# K1921VG1T register map
Vendor: NIIET; Series: K1921VGx; File version: 2.8
CPU: other r0p1, little endian, MPU, FPU, 4 interrupt priority bits
Registers are 32-bit, read-write, reset 0x0 unless marked. A register's access mark holds for its fields unless they carry their own. Offsets are from the block's base; [hi:lo] are bit positions; lines under a group give offsets from that group; {n}, {i} and the like mark numbered series; 'fields as' and 'values as' point back to an identical list.

## USBDC0 — USBDC control registers
Base 0x41080000
Same registers: USBDC1 0x41090000
{0x0+0x10*i} EPO[{i}] (i=0..3) group
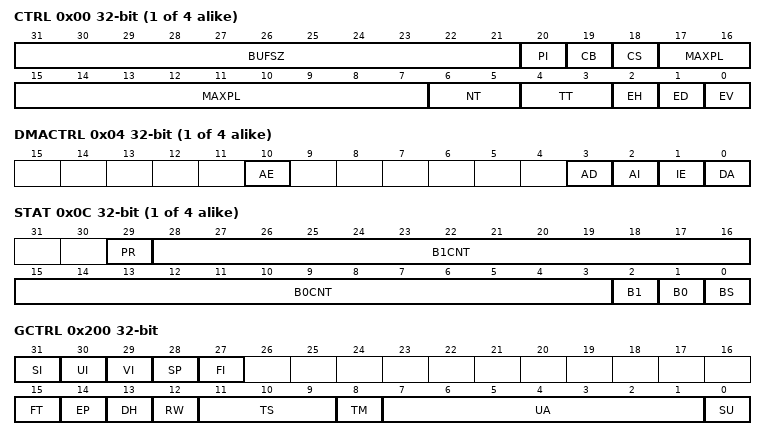
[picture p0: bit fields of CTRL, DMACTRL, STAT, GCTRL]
  0x00 CTRL — OUT Endpoint control register
    [31:21] BUFSZ ro — Buffer size
    [20] PI — Packet received interrupt
    [19] CB — Clear buffers
    [18] CS — Control stall
    [17:7] MAXPL — Maximum payload
    [6:5] NT — Number of transactions
    [4:3] TT — Transfer type
      0=CTRL (Control type of EPO); 1=ISOCH (Isochronous type of EPO); 2=BULK (Bulk type of EPO); 3=INTERRUPT (Interrupt type of EPO)
    [2] EH — Endpoint halted
    [1] ED — Endpoint disabled
    [0] EV — Endpoint valid
  0x04 DMACTRL — OUT DMA control register
    [10] AE — AHB error
    [3] AD — Abort DMA
    [2] AI — AHB error interrupt
    [1] IE — Interrupt enable
    [0] DA — Descriptors available
  0x08 DMADESC — OUT Descriptor address register
    [31:2] DESCADDR — Descriptor table address
  0x0C STAT — OUT Endpoint status register
    [29] PR — Packet received
    [28:16] B1CNT ro — Buiffer 1 byte count
    [15:3] B0CNT ro — Buiffer 0 byte count
    [2] B1 ro — Buffer 1 data valid
    [1] B0 ro — Buffer 0 data valid
    [0] BS ro — Buffer select
{0x100+0x10*i} EPI[{i}] (i=0..3) group
  0x00 CTRL — IN Endpoint control register
    [31:21] BUFSZ ro — Buffer size
    [20] PI — Packet transmitted interrupt
    [19] CB — Clear buffers
    [18] CS — Control stall
    [17:7] MAXPL — Maximum payload
    [6:5] NT — Number of transactions
    [4:3] TT — Transfer type
      0=CTRL (Control type of EPI); 1=ISOCH (Isochronous type of EPI); 2=BULK (Bulk type of EPI); 3=INTERRUPT (Interrupt type of EPI)
    [2] EH — Endpoint halted
    [1] ED — Endpoint disabled
    [0] EV — Endpoint valid
  0x04 DMACTRL — IN DMA Control register
    fields as EPO[0].DMACTRL
  0x08 DMADESC — IN Descriptor address register
    [31:2] DESCADDR — Descriptor table address
  0x0C STAT — IN Endpoint status register
    [29] PT — Packet transmitted
    [28:16] B1CNT ro — Buffer 1 byte count
    [15:3] B0CNT ro — Buffer 0 byte count
    [2] B1 ro — Buffer 1 data valid
    [1] B0 ro — Buffer 0 data valid
    [0] BS ro — Buffer select
0x200 GCTRL — USBDC Control register
  [31] SI — Suspend interrupt
  [30] UI — USB reset
  [29] VI — VBUS valid interrupt
  [28] SP — Speed mode interrupt
  [27] FI — Frame number received interrupt
  [15] FT — Functional test mode
  [14] EP — Enable Pull-Up
  [13] DH — Disable High-speed
  [12] RW — Remote wakeup
  [11:9] TS — Testmode selector
    1=Test_J (Test Mode J); 2=Test_K (Test Mode K); 3=Test_SE0_NAK (Test Mode SE0 Not ACK); 4=Test_Packet (Test Mode packet)
  [8] TM — Enable test mode
  [7:1] UA — USB address
  [0] SU wo — Set USB address
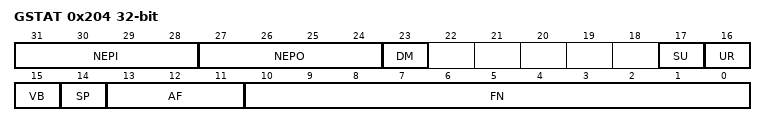
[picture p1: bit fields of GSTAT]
0x204 GSTAT — USBDC Status register
  [31:28] NEPI ro — Number of implemented IN endpoints
  [27:24] NEPO ro — Number of implemented OUT endpoints
  [23] DM ro — Data mode
    0=Slave_Data_Mode (core uses slave mode for data transfers); 1=Master_Data_Mode (core uses master mode (DMA) for data transfers)
  [17] SU ro — Suspend
  [16] UR — USB reset
  [15] VB ro — VBUS valid
  [14] SP ro — Speed
  [13:11] AF ro — Additional frames
  [10:0] FN ro — Frame number

## RTC — RTC control registers
Base 0x50005000
0x00 TIME
  [31:0] VAL — Time value
0x04 ALARM1
  [31:0] VAL — Alarm value
0x08 ALARM2
  [31:0] VAL — Alarm value
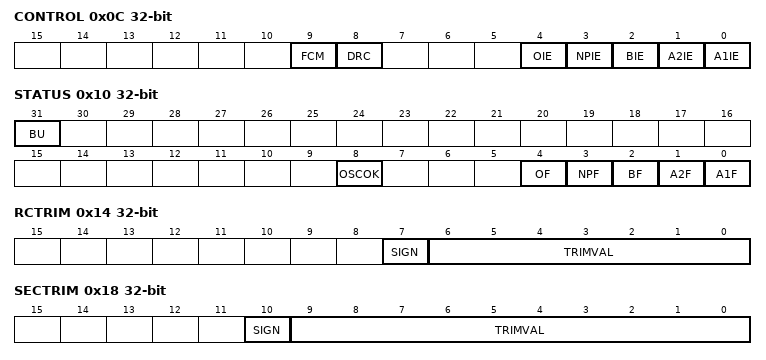
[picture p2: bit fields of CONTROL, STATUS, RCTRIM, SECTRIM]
0x0C CONTROL
  [9] FCM — Use 32kHz instead of 1Hz clock signal
    0=NORMAL_MODE (The time register is incremented each second); 1=FAST_MODE (32 kHz clock is used to increment the time register)
  [8] DRC — Disable RC generator
  [4] OIE — Timer overflow interrupt enable
  [3] NPIE — Switch to normal power supply interrupt enable
  [2] BIE — Power switched to battery interrupt enable
  [1] A2IE — Alarm 2 interrupt enable
  [0] A1IE — Alarm 1 interrupt enable
0x10 STATUS
  [31] BU ro — Battery supply is used status
  [8] OSCOK — RC oscillator state is ok
  [4] OF — Timer overflow was detected
  [3] NPF — Switch to normal power supply was detected
  [2] BF — Power switched to battery flag
  [1] A2F — Alarm 2 flag
  [0] A1F — Alarm 1 flag
0x14 RCTRIM
  [7] SIGN — Sign of trim value
  [6:0] TRIMVAL — Trim value
0x18 SECTRIM — One second clock trim register
  [10] SIGN — Sign of trim value
  [9:0] TRIMVAL — Trim value
{0x20+4i} GPR[{i}] (i=0..15) group
  0x00 VALUE — General purpose register
    [31:0] VAL — Value
